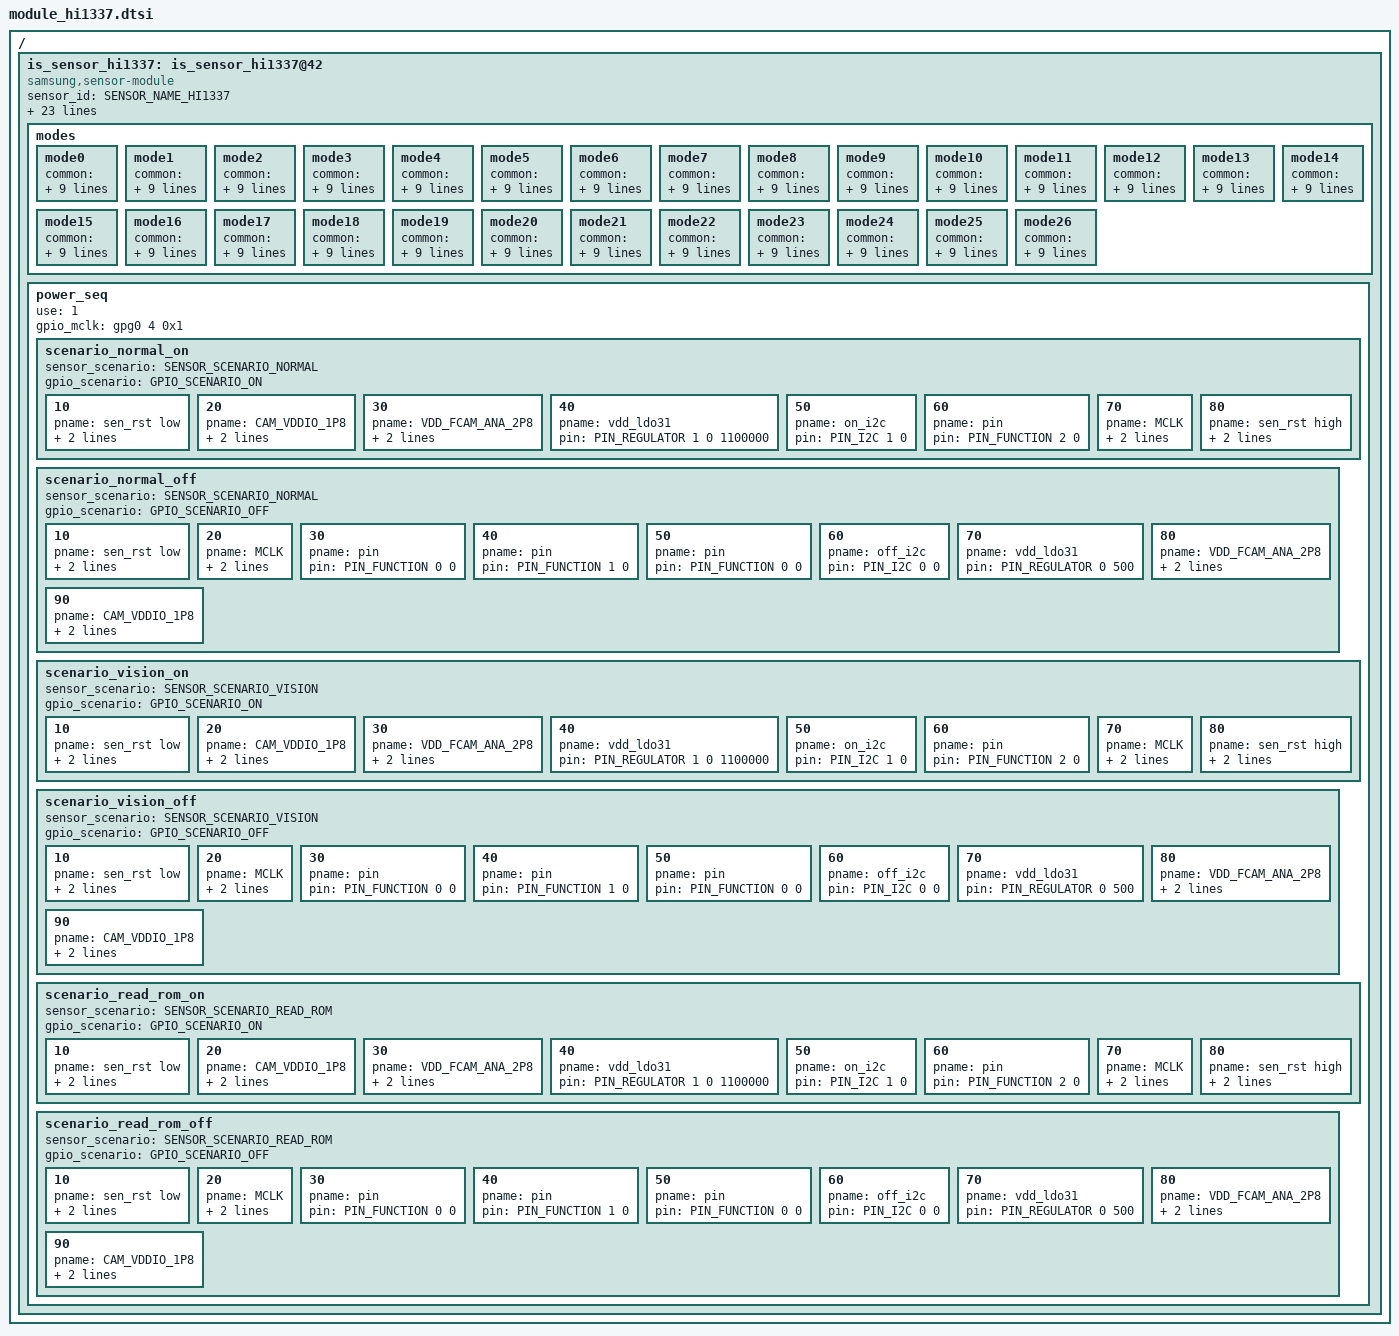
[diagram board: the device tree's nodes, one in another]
/*
 * SAMSUNG EXYNOSxxxx board camera device tree source
 *
 * Copyright (c) 2022 Samsung Electronics Co., Ltd.
 *		http://www.samsung.com
 *
 * This program is free software; you can redistribute it and/or modify
 * it under the terms of the GNU General Public License version 2 as
 * published by the Free Software Foundation.
 */

#include <dt-bindings/camera/exynos_is_dt.h>

/ {
	fragment@camera {
		target-path = "/";
		__overlay__ {
			is_sensor_hi1337: is_sensor_hi1337@42 {
				compatible = "samsung,sensor-module";

				/* common */
				sensor_id = <SENSOR_NAME_HI1337>;
				active_width = <4208>;
				active_height = <3120>;
				margin_left = <0>;
				margin_right = <0>;
				margin_top = <0>;
				margin_bottom = <0>;
				max_framerate = <120>;
				bitwidth = <10>;
				use_retention_mode = <SENSOR_RETENTION_INACTIVE>;
				sensor_maker = "HYNIX";
				sensor_name = "HI1337";
				setfile_name = "setfile_hi1337.bin";
				//pinning_setfile;
				//preload_setfile;

				status = "okay";

				/* board */
				pinctrl-names = "pin0", "pin1", "pin2", "release";
				pinctrl-0 = <>;
				pinctrl-1 = <&sensor_mclk2_out>;
				pinctrl-2 = <&sensor_mclk2_fn>;
				pinctrl-3 = <>;

				position = <1>; /* Rear:0. Front:1, Tele:2 */
				id = <1>; /* is_sensor id */
				mclk_ch = <2>;
				sensor_i2c_ch = <1>; /* SENSOR_CONTROL_I2C1 */

				/* vendor */
				rom_type = <3>; /* ROM_TYPE_OTPROM */
				rom_id = <1>;
				rom_cal_index = <0>;
#if 0
				vc_extra {
					/* ex) statX = <stat_type, sensor_mode, max_width, max_height, max_element> */
					/* VC_BUF_DATA_TYPE_SENSOR_STAT1 */
					stat0 = </*VC_STAT_TYPE_TAIL_FOR_3HDR_IMX_2_STAT0*/ 602    /*VC_SENSOR_MODE_3HDR_IMX_2*/ 602 4080 2 1>;
					/* VC_BUF_DATA_TYPE_GENERAL_STAT1 */
					stat1 = </* not available */>;
					/* VC_BUF_DATA_TYPE_SENSOR_STAT2 */
					stat2 = </*VC_STAT_TYPE_TAIL_FOR_3HDR_IMX_2_STAT1*/ 603    /*VC_SENSOR_MODE_3HDR_IMX_2*/ 602 4080 3 1>;
					/* VC_BUF_DATA_TYPE_GENERAL_STAT2 */
					stat3 = </* not available */>;
				};
#endif
				/*
				* [Mode Information]
				*
				* Reference File : Hi-1337_setting_v0.1.0.41_SEC11_20220830.xlsx
				*
				*  [ 0 ] 4000 x 3000(4:3)      @30,  MIPI lane: 4, MIPI data rate(Mbps/lane):  1495, Mclk(Mhz): 26
				*
				*/

				/* sensor modes */
				modes {
						/* common = <width, height, fps, settle, mode, lane, speed, interleave, lrte, pd_mode> */
						/* vcX = <map, hwformat, width, height, hwformat, type, width, height> */

						/* 0 : 4000x3000_30FPS */
						mode0 {
								common = <4000 3000 30 0 0 CSI_DATA_LANES_4 1404 CSI_MODE_VC_ONLY LRTE_DISABLE PD_NONE EX_NONE>;
								vc0 = </* in */ 0 HW_FORMAT_RAW10 4000 3000     /* out */ HW_FORMAT_RAW10 VC_NOTHING 4000 3000>;
								vc1 = </* in */ 1 HW_FORMAT_UNKNOWN 0 0         /* out */ HW_FORMAT_UNKNOWN VC_NOTHING 0 0>;
								vc2 = </* in */ 2 HW_FORMAT_UNKNOWN 0 0         /* out */ HW_FORMAT_UNKNOWN VC_NOTHING 0 0>;
								vc3 = </* in */ 3 HW_FORMAT_UNKNOWN 0 0         /* out */ HW_FORMAT_UNKNOWN VC_NOTHING 0 0>;
						};
						/* 1 : 4000x2256_30FPS */
						mode1 {
								common = <4000 2256 30 0 1 CSI_DATA_LANES_4 1404 CSI_MODE_VC_ONLY LRTE_DISABLE PD_NONE EX_NONE>;
								vc0 = </* in */ 0 HW_FORMAT_RAW10 4000 2256     /* out */ HW_FORMAT_RAW10 VC_NOTHING 4000 2256>;
								vc1 = </* in */ 1 HW_FORMAT_UNKNOWN 0 0         /* out */ HW_FORMAT_UNKNOWN VC_NOTHING 0 0>;
								vc2 = </* in */ 2 HW_FORMAT_UNKNOWN 0 0         /* out */ HW_FORMAT_UNKNOWN VC_NOTHING 0 0>;
								vc3 = </* in */ 3 HW_FORMAT_UNKNOWN 0 0         /* out */ HW_FORMAT_UNKNOWN VC_NOTHING 0 0>;
						};
						/* 2 : 1000x748_120FPS */
						mode2 {
								common = <1000 748 120 0 2 CSI_DATA_LANES_4 361 CSI_MODE_VC_ONLY LRTE_DISABLE PD_NONE EX_NONE>;
								vc0 = </* in */ 0 HW_FORMAT_RAW10 1000 748     /* out */ HW_FORMAT_RAW10 VC_NOTHING 1000 748>;
								vc1 = </* in */ 1 HW_FORMAT_UNKNOWN 0 0         /* out */ HW_FORMAT_UNKNOWN VC_NOTHING 0 0>;
								vc2 = </* in */ 2 HW_FORMAT_UNKNOWN 0 0         /* out */ HW_FORMAT_UNKNOWN VC_NOTHING 0 0>;
								vc3 = </* in */ 3 HW_FORMAT_UNKNOWN 0 0         /* out */ HW_FORMAT_UNKNOWN VC_NOTHING 0 0>;
						};
						/* 3 : 2000x1500_30FPS */
						mode3 {
								common = <2000 1500 30 0 3 CSI_DATA_LANES_4 361 CSI_MODE_VC_ONLY LRTE_DISABLE PD_NONE EX_NONE>;
								vc0 = </* in */ 0 HW_FORMAT_RAW10 2000 1500     /* out */ HW_FORMAT_RAW10 VC_NOTHING 2000 1500>;
								vc1 = </* in */ 1 HW_FORMAT_UNKNOWN 0 0         /* out */ HW_FORMAT_UNKNOWN VC_NOTHING 0 0>;
								vc2 = </* in */ 2 HW_FORMAT_UNKNOWN 0 0         /* out */ HW_FORMAT_UNKNOWN VC_NOTHING 0 0>;
								vc3 = </* in */ 3 HW_FORMAT_UNKNOWN 0 0         /* out */ HW_FORMAT_UNKNOWN VC_NOTHING 0 0>;
						};
						/* 4 : 4128x3096_30FPS */
						mode4 {
								common = <4128 3096 30 0 4 CSI_DATA_LANES_4 1404 CSI_MODE_VC_ONLY LRTE_DISABLE PD_NONE EX_NONE>;
								vc0 = </* in */ 0 HW_FORMAT_RAW10 4128 3096     /* out */ HW_FORMAT_RAW10 VC_NOTHING 4128 3096>;
								vc1 = </* in */ 1 HW_FORMAT_UNKNOWN 0 0         /* out */ HW_FORMAT_UNKNOWN VC_NOTHING 0 0>;
								vc2 = </* in */ 2 HW_FORMAT_UNKNOWN 0 0         /* out */ HW_FORMAT_UNKNOWN VC_NOTHING 0 0>;
								vc3 = </* in */ 3 HW_FORMAT_UNKNOWN 0 0         /* out */ HW_FORMAT_UNKNOWN VC_NOTHING 0 0>;
						};
						/* 5 : 3408x2556_30FPS */
						mode5 {
								common = <3408 2556 30 0 5 CSI_DATA_LANES_4 1404 CSI_MODE_VC_ONLY LRTE_DISABLE PD_NONE EX_NONE>;
								vc0 = </* in */ 0 HW_FORMAT_RAW10 3408 2556     /* out */ HW_FORMAT_RAW10 VC_NOTHING 3408 2556>;
								vc1 = </* in */ 1 HW_FORMAT_UNKNOWN 0 0         /* out */ HW_FORMAT_UNKNOWN VC_NOTHING 0 0>;
								vc2 = </* in */ 2 HW_FORMAT_UNKNOWN 0 0         /* out */ HW_FORMAT_UNKNOWN VC_NOTHING 0 0>;
								vc3 = </* in */ 3 HW_FORMAT_UNKNOWN 0 0         /* out */ HW_FORMAT_UNKNOWN VC_NOTHING 0 0>;
						};
						/* 6 : 3344x1880_30FPS */
						mode6 {
								common = <3344 1880 30 0 6 CSI_DATA_LANES_4 1404 CSI_MODE_VC_ONLY LRTE_DISABLE PD_NONE EX_NONE>;
								vc0 = </* in */ 0 HW_FORMAT_RAW10 3344 1880     /* out */ HW_FORMAT_RAW10 VC_NOTHING 3344 1880>;
								vc1 = </* in */ 1 HW_FORMAT_UNKNOWN 0 0         /* out */ HW_FORMAT_UNKNOWN VC_NOTHING 0 0>;
								vc2 = </* in */ 2 HW_FORMAT_UNKNOWN 0 0         /* out */ HW_FORMAT_UNKNOWN VC_NOTHING 0 0>;
								vc3 = </* in */ 3 HW_FORMAT_UNKNOWN 0 0         /* out */ HW_FORMAT_UNKNOWN VC_NOTHING 0 0>;
						};
						/* 7 : 3200x2400_30FPS */
						mode7 {
								common = <3200 2400 30 0 7 CSI_DATA_LANES_4 1404 CSI_MODE_VC_ONLY LRTE_DISABLE PD_NONE EX_NONE>;
								vc0 = </* in */ 0 HW_FORMAT_RAW10 3200 2400     /* out */ HW_FORMAT_RAW10 VC_NOTHING 3200 2400>;
								vc1 = </* in */ 1 HW_FORMAT_UNKNOWN 0 0         /* out */ HW_FORMAT_UNKNOWN VC_NOTHING 0 0>;
								vc2 = </* in */ 2 HW_FORMAT_UNKNOWN 0 0         /* out */ HW_FORMAT_UNKNOWN VC_NOTHING 0 0>;
								vc3 = </* in */ 3 HW_FORMAT_UNKNOWN 0 0         /* out */ HW_FORMAT_UNKNOWN VC_NOTHING 0 0>;
						};
						/* 8 : 3172x2580_30FPS */
						mode8 {
								common = <3172 2580 30 0 8 CSI_DATA_LANES_4 1404 CSI_MODE_VC_ONLY LRTE_DISABLE PD_NONE EX_NONE>;
								vc0 = </* in */ 0 HW_FORMAT_RAW10 3172 2580     /* out */ HW_FORMAT_RAW10 VC_NOTHING 3172 2580>;
								vc1 = </* in */ 1 HW_FORMAT_UNKNOWN 0 0         /* out */ HW_FORMAT_UNKNOWN VC_NOTHING 0 0>;
								vc2 = </* in */ 2 HW_FORMAT_UNKNOWN 0 0         /* out */ HW_FORMAT_UNKNOWN VC_NOTHING 0 0>;
								vc3 = </* in */ 3 HW_FORMAT_UNKNOWN 0 0         /* out */ HW_FORMAT_UNKNOWN VC_NOTHING 0 0>;
						};
						/* 9 : 3172x2040_30FPS */
						mode9 {
								common = <3172 2040 30 0 9 CSI_DATA_LANES_4 1404 CSI_MODE_VC_ONLY LRTE_DISABLE PD_NONE EX_NONE>;
								vc0 = </* in */ 0 HW_FORMAT_RAW10 3172 2040     /* out */ HW_FORMAT_RAW10 VC_NOTHING 3172 2040>;
								vc1 = </* in */ 1 HW_FORMAT_UNKNOWN 0 0         /* out */ HW_FORMAT_UNKNOWN VC_NOTHING 0 0>;
								vc2 = </* in */ 2 HW_FORMAT_UNKNOWN 0 0         /* out */ HW_FORMAT_UNKNOWN VC_NOTHING 0 0>;
								vc3 = </* in */ 3 HW_FORMAT_UNKNOWN 0 0         /* out */ HW_FORMAT_UNKNOWN VC_NOTHING 0 0>;
						};
						/* 10 : 4208x3120_30FPS */
						mode10 {
								common = <4208 3120 30 0 10 CSI_DATA_LANES_4 1404 CSI_MODE_VC_ONLY LRTE_DISABLE PD_NONE EX_NONE>;
								vc0 = </* in */ 0 HW_FORMAT_RAW10 4208 3120     /* out */ HW_FORMAT_RAW10 VC_NOTHING 4208 3120>;
								vc1 = </* in */ 1 HW_FORMAT_UNKNOWN 0 0         /* out */ HW_FORMAT_UNKNOWN VC_NOTHING 0 0>;
								vc2 = </* in */ 2 HW_FORMAT_UNKNOWN 0 0         /* out */ HW_FORMAT_UNKNOWN VC_NOTHING 0 0>;
								vc3 = </* in */ 3 HW_FORMAT_UNKNOWN 0 0         /* out */ HW_FORMAT_UNKNOWN VC_NOTHING 0 0>;
						};
						/* 11 : 4128x2320_30FPS */
						mode11 {
								common = <4128 2320 30 0 11 CSI_DATA_LANES_4 1404 CSI_MODE_VC_ONLY LRTE_DISABLE PD_NONE EX_NONE>;
								vc0 = </* in */ 0 HW_FORMAT_RAW10 4128 2320     /* out */ HW_FORMAT_RAW10 VC_NOTHING 4128 2320>;
								vc1 = </* in */ 1 HW_FORMAT_UNKNOWN 0 0         /* out */ HW_FORMAT_UNKNOWN VC_NOTHING 0 0>;
								vc2 = </* in */ 2 HW_FORMAT_UNKNOWN 0 0         /* out */ HW_FORMAT_UNKNOWN VC_NOTHING 0 0>;
								vc3 = </* in */ 3 HW_FORMAT_UNKNOWN 0 0         /* out */ HW_FORMAT_UNKNOWN VC_NOTHING 0 0>;
						};
						/* 12: 2032x1524_30FPS */
						mode12 {
								common = <2032 1524 30 0 12 CSI_DATA_LANES_4 1404 CSI_MODE_VC_ONLY LRTE_DISABLE PD_NONE EX_NONE>;
								vc0 = </* in */ 0 HW_FORMAT_RAW10 2032 1524     /* out */ HW_FORMAT_RAW10 VC_NOTHING 2032 1524>;
								vc1 = </* in */ 1 HW_FORMAT_UNKNOWN 0 0         /* out */ HW_FORMAT_UNKNOWN VC_NOTHING 0 0>;
								vc2 = </* in */ 2 HW_FORMAT_UNKNOWN 0 0         /* out */ HW_FORMAT_UNKNOWN VC_NOTHING 0 0>;
								vc3 = </* in */ 3 HW_FORMAT_UNKNOWN 0 0         /* out */ HW_FORMAT_UNKNOWN VC_NOTHING 0 0>;
						};
						/* 13: 2560x1920_30FPS */
						mode13 {
								common = <2560 1920 30 0 13 CSI_DATA_LANES_4 1404 CSI_MODE_VC_ONLY LRTE_DISABLE PD_NONE EX_NONE>;
								vc0 = </* in */ 0 HW_FORMAT_RAW10 2560 1920     /* out */ HW_FORMAT_RAW10 VC_NOTHING 2560 1920>;
								vc1 = </* in */ 1 HW_FORMAT_UNKNOWN 0 0         /* out */ HW_FORMAT_UNKNOWN VC_NOTHING 0 0>;
								vc2 = </* in */ 2 HW_FORMAT_UNKNOWN 0 0         /* out */ HW_FORMAT_UNKNOWN VC_NOTHING 0 0>;
								vc3 = </* in */ 3 HW_FORMAT_UNKNOWN 0 0         /* out */ HW_FORMAT_UNKNOWN VC_NOTHING 0 0>;
						};
						/* 14: 2560x1440_30FPS */
						mode14 {
								common = <2560 1440 30 0 14 CSI_DATA_LANES_4 1404 CSI_MODE_VC_ONLY LRTE_DISABLE PD_NONE EX_NONE>;
								vc0 = </* in */ 0 HW_FORMAT_RAW10 2560 1440     /* out */ HW_FORMAT_RAW10 VC_NOTHING 2560 1440>;
								vc1 = </* in */ 1 HW_FORMAT_UNKNOWN 0 0         /* out */ HW_FORMAT_UNKNOWN VC_NOTHING 0 0>;
								vc2 = </* in */ 2 HW_FORMAT_UNKNOWN 0 0         /* out */ HW_FORMAT_UNKNOWN VC_NOTHING 0 0>;
								vc3 = </* in */ 3 HW_FORMAT_UNKNOWN 0 0         /* out */ HW_FORMAT_UNKNOWN VC_NOTHING 0 0>;
						};
						/* 15: 2560x1600_30FPS */
						mode15 {
								common = <2560 1600 30 0 15 CSI_DATA_LANES_4 1404 CSI_MODE_VC_ONLY LRTE_DISABLE PD_NONE EX_NONE>;
								vc0 = </* in */ 0 HW_FORMAT_RAW10 2560 1600     /* out */ HW_FORMAT_RAW10 VC_NOTHING 2560 1600>;
								vc1 = </* in */ 1 HW_FORMAT_UNKNOWN 0 0         /* out */ HW_FORMAT_UNKNOWN VC_NOTHING 0 0>;
								vc2 = </* in */ 2 HW_FORMAT_UNKNOWN 0 0         /* out */ HW_FORMAT_UNKNOWN VC_NOTHING 0 0>;
								vc3 = </* in */ 3 HW_FORMAT_UNKNOWN 0 0         /* out */ HW_FORMAT_UNKNOWN VC_NOTHING 0 0>;
						};
						/* 16: 1920x1920_30FPS */
						mode16 {
								common = <1920 1920 30 0 16 CSI_DATA_LANES_4 1404 CSI_MODE_VC_ONLY LRTE_DISABLE PD_NONE EX_NONE>;
								vc0 = </* in */ 0 HW_FORMAT_RAW10 1920 1920     /* out */ HW_FORMAT_RAW10 VC_NOTHING 1920 1920>;
								vc1 = </* in */ 1 HW_FORMAT_UNKNOWN 0 0         /* out */ HW_FORMAT_UNKNOWN VC_NOTHING 0 0>;
								vc2 = </* in */ 2 HW_FORMAT_UNKNOWN 0 0         /* out */ HW_FORMAT_UNKNOWN VC_NOTHING 0 0>;
								vc3 = </* in */ 3 HW_FORMAT_UNKNOWN 0 0         /* out */ HW_FORMAT_UNKNOWN VC_NOTHING 0 0>;
						};
						/* 17: 992x744_120FPS */
						mode17 {
								common = <992 744 120 0 17 CSI_DATA_LANES_4 361 CSI_MODE_VC_ONLY LRTE_DISABLE PD_NONE EX_NONE>;
								vc0 = </* in */ 0 HW_FORMAT_RAW10 992 744     /* out */ HW_FORMAT_RAW10 VC_NOTHING 992 744>;
								vc1 = </* in */ 1 HW_FORMAT_UNKNOWN 0 0         /* out */ HW_FORMAT_UNKNOWN VC_NOTHING 0 0>;
								vc2 = </* in */ 2 HW_FORMAT_UNKNOWN 0 0         /* out */ HW_FORMAT_UNKNOWN VC_NOTHING 0 0>;
								vc3 = </* in */ 3 HW_FORMAT_UNKNOWN 0 0         /* out */ HW_FORMAT_UNKNOWN VC_NOTHING 0 0>;
						};
						/* 18: 2000x1124_30FPS */
						mode18 {
								common = <2000 1124 30 0 18 CSI_DATA_LANES_4 685 CSI_MODE_VC_ONLY LRTE_DISABLE PD_NONE EX_NONE>;
								vc0 = </* in */ 0 HW_FORMAT_RAW10 2000 1124     /* out */ HW_FORMAT_RAW10 VC_NOTHING 2000 1124>;
								vc1 = </* in */ 1 HW_FORMAT_UNKNOWN 0 0         /* out */ HW_FORMAT_UNKNOWN VC_NOTHING 0 0>;
								vc2 = </* in */ 2 HW_FORMAT_UNKNOWN 0 0         /* out */ HW_FORMAT_UNKNOWN VC_NOTHING 0 0>;
								vc3 = </* in */ 3 HW_FORMAT_UNKNOWN 0 0         /* out */ HW_FORMAT_UNKNOWN VC_NOTHING 0 0>;
						};
						/* 19: 1280x960_30FPS */
						mode19 {
								common = <1280 960 30 0 19 CSI_DATA_LANES_4 685 CSI_MODE_VC_ONLY LRTE_DISABLE PD_NONE EX_NONE>;
								vc0 = </* in */ 0 HW_FORMAT_RAW10 1280 960     /* out */ HW_FORMAT_RAW10 VC_NOTHING 1280 960>;
								vc1 = </* in */ 1 HW_FORMAT_UNKNOWN 0 0         /* out */ HW_FORMAT_UNKNOWN VC_NOTHING 0 0>;
								vc2 = </* in */ 2 HW_FORMAT_UNKNOWN 0 0         /* out */ HW_FORMAT_UNKNOWN VC_NOTHING 0 0>;
								vc3 = </* in */ 3 HW_FORMAT_UNKNOWN 0 0         /* out */ HW_FORMAT_UNKNOWN VC_NOTHING 0 0>;
						};
						/* 20: 1280x720_30FPS */
						mode20 {
								common = <1280 720 30 0 20 CSI_DATA_LANES_4 685 CSI_MODE_VC_ONLY LRTE_DISABLE PD_NONE EX_NONE>;
								vc0 = </* in */ 0 HW_FORMAT_RAW10 1280 720     /* out */ HW_FORMAT_RAW10 VC_NOTHING 1280 720>;
								vc1 = </* in */ 1 HW_FORMAT_UNKNOWN 0 0         /* out */ HW_FORMAT_UNKNOWN VC_NOTHING 0 0>;
								vc2 = </* in */ 2 HW_FORMAT_UNKNOWN 0 0         /* out */ HW_FORMAT_UNKNOWN VC_NOTHING 0 0>;
								vc3 = </* in */ 3 HW_FORMAT_UNKNOWN 0 0         /* out */ HW_FORMAT_UNKNOWN VC_NOTHING 0 0>;
						};
						/* 21: 2368x1776_30FPS */
						mode21 {
								common = <2368 1776 30 0 21 CSI_DATA_LANES_4 685 CSI_MODE_VC_ONLY LRTE_DISABLE PD_NONE EX_NONE>;
								vc0 = </* in */ 0 HW_FORMAT_RAW10 2368 1776     /* out */ HW_FORMAT_RAW10 VC_NOTHING 2368 1776>;
								vc1 = </* in */ 1 HW_FORMAT_UNKNOWN 0 0         /* out */ HW_FORMAT_UNKNOWN VC_NOTHING 0 0>;
								vc2 = </* in */ 2 HW_FORMAT_UNKNOWN 0 0         /* out */ HW_FORMAT_UNKNOWN VC_NOTHING 0 0>;
								vc3 = </* in */ 3 HW_FORMAT_UNKNOWN 0 0         /* out */ HW_FORMAT_UNKNOWN VC_NOTHING 0 0>;
						};
						/* 22: 2368x1332_30FPS */
						mode22 {
								common = <2368 1332 30 0 22 CSI_DATA_LANES_4 685 CSI_MODE_VC_ONLY LRTE_DISABLE PD_NONE EX_NONE>;
								vc0 = </* in */ 0 HW_FORMAT_RAW10 2368 1332     /* out */ HW_FORMAT_RAW10 VC_NOTHING 2368 1332>;
								vc1 = </* in */ 1 HW_FORMAT_UNKNOWN 0 0         /* out */ HW_FORMAT_UNKNOWN VC_NOTHING 0 0>;
								vc2 = </* in */ 2 HW_FORMAT_UNKNOWN 0 0         /* out */ HW_FORMAT_UNKNOWN VC_NOTHING 0 0>;
								vc3 = </* in */ 3 HW_FORMAT_UNKNOWN 0 0         /* out */ HW_FORMAT_UNKNOWN VC_NOTHING 0 0>;
						};
						/* 23: 2368x1480_30FPS */
						mode23 {
								common = <2368 1480 30 0 23 CSI_DATA_LANES_4 685 CSI_MODE_VC_ONLY LRTE_DISABLE PD_NONE EX_NONE>;
								vc0 = </* in */ 0 HW_FORMAT_RAW10 2368 1480     /* out */ HW_FORMAT_RAW10 VC_NOTHING 2368 1480>;
								vc1 = </* in */ 1 HW_FORMAT_UNKNOWN 0 0         /* out */ HW_FORMAT_UNKNOWN VC_NOTHING 0 0>;
								vc2 = </* in */ 2 HW_FORMAT_UNKNOWN 0 0         /* out */ HW_FORMAT_UNKNOWN VC_NOTHING 0 0>;
								vc3 = </* in */ 3 HW_FORMAT_UNKNOWN 0 0         /* out */ HW_FORMAT_UNKNOWN VC_NOTHING 0 0>;
						};
						/* 24: 1776x1776_30FPS */
						mode24 {
								common = <1776 1776 30 0 24 CSI_DATA_LANES_4 685 CSI_MODE_VC_ONLY LRTE_DISABLE PD_NONE EX_NONE>;
								vc0 = </* in */ 0 HW_FORMAT_RAW10 1776 1776     /* out */ HW_FORMAT_RAW10 VC_NOTHING 1776 1776>;
								vc1 = </* in */ 1 HW_FORMAT_UNKNOWN 0 0         /* out */ HW_FORMAT_UNKNOWN VC_NOTHING 0 0>;
								vc2 = </* in */ 2 HW_FORMAT_UNKNOWN 0 0         /* out */ HW_FORMAT_UNKNOWN VC_NOTHING 0 0>;
								vc3 = </* in */ 3 HW_FORMAT_UNKNOWN 0 0         /* out */ HW_FORMAT_UNKNOWN VC_NOTHING 0 0>;
						};
						/* 25: 1016x762_30FPS */
						mode25 {
								common = <1016 762 30 0 25 CSI_DATA_LANES_4 685 CSI_MODE_VC_ONLY LRTE_DISABLE PD_NONE EX_NONE>;
								vc0 = </* in */ 0 HW_FORMAT_RAW10 1016 762     /* out */ HW_FORMAT_RAW10 VC_NOTHING 1016 762>;
								vc1 = </* in */ 1 HW_FORMAT_UNKNOWN 0 0         /* out */ HW_FORMAT_UNKNOWN VC_NOTHING 0 0>;
								vc2 = </* in */ 2 HW_FORMAT_UNKNOWN 0 0         /* out */ HW_FORMAT_UNKNOWN VC_NOTHING 0 0>;
								vc3 = </* in */ 3 HW_FORMAT_UNKNOWN 0 0         /* out */ HW_FORMAT_UNKNOWN VC_NOTHING 0 0>;
						};

						mode26 {
								// FOR SECURE CAMERA FD SCENARIO
								common = <2032 1524 30 0 12 CSI_DATA_LANES_4 1404 CSI_MODE_VC_ONLY LRTE_DISABLE PD_NONE EX_PDSTAT_OFF>;
								vc0 = </* in */ 0 HW_FORMAT_RAW10 2032 1524     /* out */ HW_FORMAT_RAW10 VC_NOTHING 2032 1524>;
								vc1 = </* in */ 1 HW_FORMAT_UNKNOWN 0 0         /* out */ HW_FORMAT_UNKNOWN VC_NOTHING 0 0>;
								vc2 = </* in */ 2 HW_FORMAT_UNKNOWN 0 0         /* out */ HW_FORMAT_UNKNOWN VC_NOTHING 0 0>;
								vc3 = </* in */ 3 HW_FORMAT_UNKNOWN 0 0         /* out */ HW_FORMAT_UNKNOWN VC_NOTHING 0 0>;
						};
				};

				power_seq {
					use = <1>;
					gpio_mclk = <&gpg0 4 0x1>;

					scenario_normal_on {
						sensor_scenario = <SENSOR_SCENARIO_NORMAL>;
						gpio_scenario = <GPIO_SCENARIO_ON>;

						/* A start node number should be over the 10 for reserved number 0~9. */
						/* pname = "name"; pin = <act value dealy voltage>; gpio = <gpx# # 0x1>; */
						10 { pname = "sen_rst low"; pin = <PIN_OUTPUT 0 0>; gpio = <&gpm9 0 0x1>; };
						20 { pname = "CAM_VDDIO_1P8"; pin = <PIN_OUTPUT 1 0>; gpio = <&gpc11 0 0x1>; };
						30 { pname = "VDD_FCAM_ANA_2P8"; pin = <PIN_OUTPUT 1 0>; gpio = <&gpc8 0 0x1>; };
						40 { pname = "vdd_ldo31"; pin = <PIN_REGULATOR 1 0 1100000>; };
						50 { pname = "on_i2c"; pin = <PIN_I2C 1 0>; };
						60 { pname = "pin"; pin = <PIN_FUNCTION 2 0>; };
						70 { pname = "MCLK"; pin = <PIN_MCLK 1 0>; gpio = <&gpg0 4 0x1>; };
						80 { pname = "sen_rst high"; pin = <PIN_OUTPUT 1 2000>; gpio = <&gpm9 0 0x1>; };
					};

					scenario_normal_off {
						sensor_scenario = <SENSOR_SCENARIO_NORMAL>;
						gpio_scenario = <GPIO_SCENARIO_OFF>;

						/* A start node number should be over the 10 for reserved number 0~9. */
						/* pname = "name"; pin = <act value dealy voltage>; gpio = <gpx# # 0x1>; */
						10 { pname = "sen_rst low"; pin = <PIN_OUTPUT 0 1000>; gpio = <&gpm9 0 0x1>; };
						20 { pname = "MCLK"; pin = <PIN_MCLK 0 500>; gpio = <&gpg0 4 0x1>; };
						30 { pname = "pin"; pin = <PIN_FUNCTION 0 0>; };
						40 { pname = "pin"; pin = <PIN_FUNCTION 1 0>; };
						50 { pname = "pin"; pin = <PIN_FUNCTION 0 0>; };
						60 { pname = "off_i2c"; pin = <PIN_I2C 0 0>; };
						70 { pname = "vdd_ldo31"; pin = <PIN_REGULATOR 0 500>; };
						80 { pname = "VDD_FCAM_ANA_2P8"; pin = <PIN_OUTPUT 0 0>; gpio = <&gpc8 0 0x1>; };
						90 { pname = "CAM_VDDIO_1P8"; pin = <PIN_OUTPUT 0 0>;  gpio = <&gpc11 0 0x1>;};
					};
					scenario_vision_on {
						sensor_scenario = <SENSOR_SCENARIO_VISION>;
						gpio_scenario = <GPIO_SCENARIO_ON>;

						/* A start node number should be over the 10 for reserved number 0~9. */
						/* pname = "name"; pin = <act value dealy voltage>; gpio = <gpx# # 0x1>; */
						10 { pname = "sen_rst low"; pin = <PIN_OUTPUT 0 0>; gpio = <&gpm9 0 0x1>; };
						20 { pname = "CAM_VDDIO_1P8"; pin = <PIN_OUTPUT 1 0>; gpio = <&gpc11 0 0x1>; };
						30 { pname = "VDD_FCAM_ANA_2P8"; pin = <PIN_OUTPUT 1 0>; gpio = <&gpc8 0 0x1>; };
						40 { pname = "vdd_ldo31"; pin = <PIN_REGULATOR 1 0 1100000>; };
						50 { pname = "on_i2c"; pin = <PIN_I2C 1 0>; };
						60 { pname = "pin"; pin = <PIN_FUNCTION 2 0>; };
						70 { pname = "MCLK"; pin = <PIN_MCLK 1 0>; gpio = <&gpg0 4 0x1>; };
						80 { pname = "sen_rst high"; pin = <PIN_OUTPUT 1 2000>; gpio = <&gpm9 0 0x1>; };
					};

					scenario_vision_off {
						sensor_scenario = <SENSOR_SCENARIO_VISION>;
						gpio_scenario = <GPIO_SCENARIO_OFF>;

						/* A start node number should be over the 10 for reserved number 0~9. */
						/* pname = "name"; pin = <act value dealy voltage>; gpio = <gpx# # 0x1>; */
						10 { pname = "sen_rst low"; pin = <PIN_OUTPUT 0 1000>; gpio = <&gpm9 0 0x1>; };
						20 { pname = "MCLK"; pin = <PIN_MCLK 0 500>; gpio = <&gpg0 4 0x1>; };
						30 { pname = "pin"; pin = <PIN_FUNCTION 0 0>; };
						40 { pname = "pin"; pin = <PIN_FUNCTION 1 0>; };
						50 { pname = "pin"; pin = <PIN_FUNCTION 0 0>; };
						60 { pname = "off_i2c"; pin = <PIN_I2C 0 0>; };
						70 { pname = "vdd_ldo31"; pin = <PIN_REGULATOR 0 500>; };
						80 { pname = "VDD_FCAM_ANA_2P8"; pin = <PIN_OUTPUT 0 0>; gpio = <&gpc8 0 0x1>; };
						90 { pname = "CAM_VDDIO_1P8"; pin = <PIN_OUTPUT 0 0>; gpio = <&gpc11 0 0x1>; };
					};

					scenario_read_rom_on {
						sensor_scenario = <SENSOR_SCENARIO_READ_ROM>;
						gpio_scenario = <GPIO_SCENARIO_ON>;

						/* A start node number should be over the 10 for reserved number 0~9. */
						/* pname = "name"; pin = <act value dealy voltage>; gpio = <gpx# # 0x1>; */
						10 { pname = "sen_rst low"; pin = <PIN_OUTPUT 0 0>; gpio = <&gpm9 0 0x1>; };
						20 { pname = "CAM_VDDIO_1P8"; pin = <PIN_OUTPUT 1 0>; gpio = <&gpc11 0 0x1>; };
						30 { pname = "VDD_FCAM_ANA_2P8"; pin = <PIN_OUTPUT 1 0>; gpio = <&gpc8 0 0x1>; };
						40 { pname = "vdd_ldo31"; pin = <PIN_REGULATOR 1 0 1100000>; };
						50 { pname = "on_i2c"; pin = <PIN_I2C 1 0>; };
						60 { pname = "pin"; pin = <PIN_FUNCTION 2 0>; };
						70 { pname = "MCLK"; pin = <PIN_MCLK 1 0>; gpio = <&gpg0 4 0x1>; };
						80 { pname = "sen_rst high"; pin = <PIN_OUTPUT 1 2000>; gpio = <&gpm9 0 0x1>; };
					};

					scenario_read_rom_off {
						sensor_scenario = <SENSOR_SCENARIO_READ_ROM>;
						gpio_scenario = <GPIO_SCENARIO_OFF>;

						/* A start node number should be over the 10 for reserved number 0~9. */
						/* pname = "name"; pin = <act value dealy voltage>; gpio = <gpx# # 0x1>; */
						10 { pname = "sen_rst low"; pin = <PIN_OUTPUT 0 1000>; gpio = <&gpm9 0 0x1>; };
						20 { pname = "MCLK"; pin = <PIN_MCLK 0 500>; gpio = <&gpg0 4 0x1>; };
						30 { pname = "pin"; pin = <PIN_FUNCTION 0 0>; };
						40 { pname = "pin"; pin = <PIN_FUNCTION 1 0>; };
						50 { pname = "pin"; pin = <PIN_FUNCTION 0 0>; };
						60 { pname = "off_i2c"; pin = <PIN_I2C 0 0>; };
						70 { pname = "vdd_ldo31"; pin = <PIN_REGULATOR 0 500>; };
						80 { pname = "VDD_FCAM_ANA_2P8"; pin = <PIN_OUTPUT 0 0>; gpio = <&gpc8 0 0x1>; };
						90 { pname = "CAM_VDDIO_1P8"; pin = <PIN_OUTPUT 0 0>; gpio = <&gpc11 0 0x1>; };
					};
				};
			};
		}; /* end of __overlay__ */
	}; /* end of fragment */
}; /* end of root */
